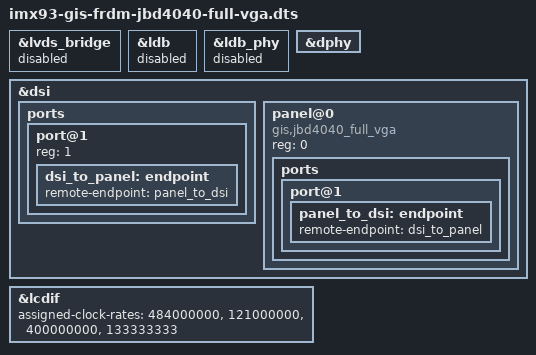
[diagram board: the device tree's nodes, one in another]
// SPDX-License-Identifier: (GPL-2.0+ OR MIT)
/*
 * Copyright 2024 NXP
 */

//#include "imx93-gis-sdmb.dts"
#include "imx93-gis-frdm-test-jbd4040.dts"
#include <dt-bindings/clock/imx93-clock.h>

&lvds_bridge {
	status = "disabled";
};

&ldb {
	status = "disabled";
};

&ldb_phy {
	status = "disabled";
};

&dphy {
	status = "okay";
};

&dsi {
    status = "okay";

    ports {
        port@1{
            reg = <1>;

            dsi_to_panel: endpoint {
                remote-endpoint = <&panel_to_dsi>;
            };
        };
    };

    panel@0{
        reg = <0>;
        //compatible = "ws,ws_800x480";
        compatible = "gis,jbd4040_full_vga";

        ports {
            port@1{
                panel_to_dsi: endpoint {
                    remote-endpoint = <&dsi_to_panel>;
                };
            };
        };
    };
};

&lcdif {
	assigned-clock-rates = <484000000>, <121000000>, <400000000>, <133333333>;
	//assigned-clock-rates = <400000000>, <133300000>, <400000000>, <133333333>;
        status = "okay";
	//assigned-clock-rates = <484000000>, <13330000>, <400000000>, <133333333>;
        //status = "okay";

};

